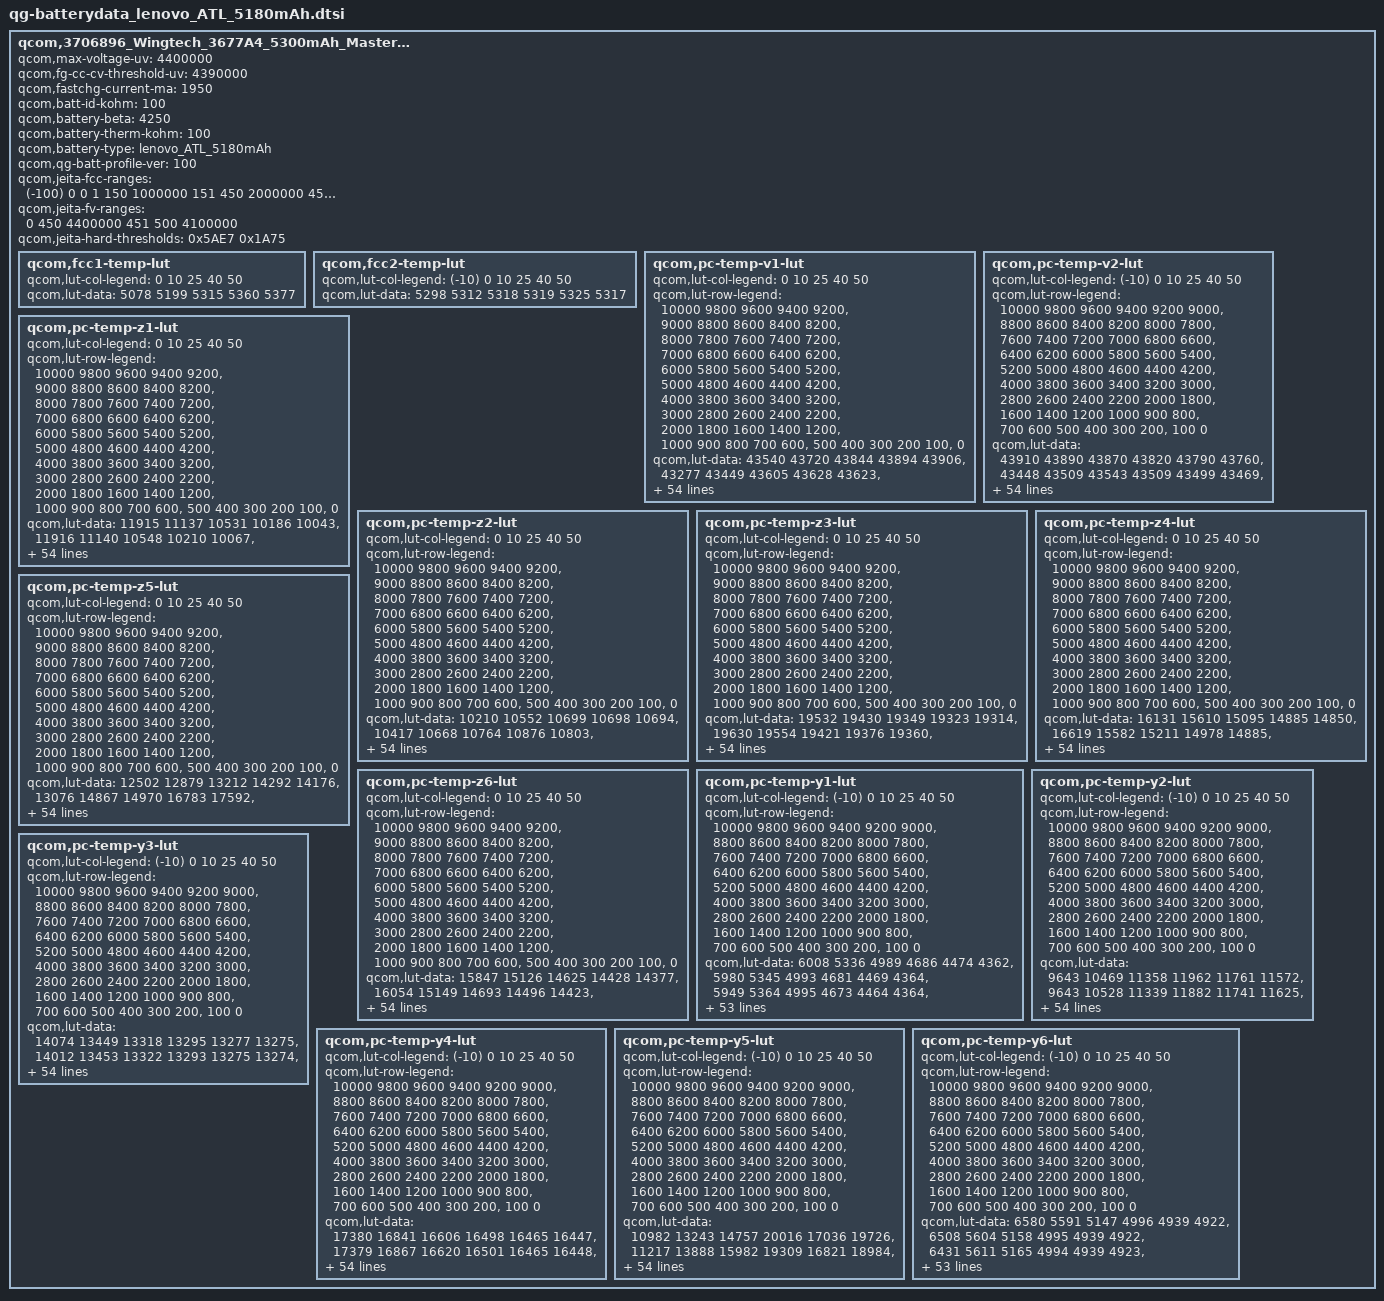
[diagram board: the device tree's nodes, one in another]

qcom,3706896_Wingtech_3677A4_5300mAh_Master_Oct16th2018 {
    /* 3706896_Wingtech_3677A4_5300mAh_Master_Oct16th2018 */
    qcom,max-voltage-uv = <4400000>;
    qcom,fg-cc-cv-threshold-uv = <4390000>;
    qcom,fastchg-current-ma = <1950>;
    qcom,batt-id-kohm = <100>;
    qcom,battery-beta = <4250>;
    qcom,battery-therm-kohm = <100>;
    qcom,battery-type = "lenovo_ATL_5180mAh";
    qcom,qg-batt-profile-ver = <100>;
    qcom,jeita-fcc-ranges = <(-100) 0 0
                       1 150 1000000
                       151 450 2000000
			451 500 1200000
			501 510 0>;
    qcom,jeita-fv-ranges = <0 450 4400000
                       451 500 4100000>;
    qcom,jeita-hard-thresholds = <0x5AE7 0x1A75>;

	qcom,fcc1-temp-lut {
		qcom,lut-col-legend = <0 10 25 40 50>;
		qcom,lut-data = <5078 5199 5315 5360 5377>;
	};

	qcom,fcc2-temp-lut {
		qcom,lut-col-legend = <(-10) 0 10 25 40 50>;
		qcom,lut-data = <5298 5312 5318 5319 5325 5317>;
	};

	qcom,pc-temp-v1-lut {
		qcom,lut-col-legend = <0 10 25 40 50>;
		qcom,lut-row-legend = <10000 9800 9600 9400 9200>,
			<9000 8800 8600 8400 8200>,
			<8000 7800 7600 7400 7200>,
			<7000 6800 6600 6400 6200>,
			<6000 5800 5600 5400 5200>,
			<5000 4800 4600 4400 4200>,
			<4000 3800 3600 3400 3200>,
			<3000 2800 2600 2400 2200>,
			<2000 1800 1600 1400 1200>,
			<1000 900 800 700 600>,
			<500 400 300 200 100>,
			<0>;
		qcom,lut-data = <43540 43720 43844 43894 43906>,
			<43277 43449 43605 43628 43623>,
			<43017 43194 43347 43384 43378>,
			<42765 42955 43098 43148 43144>,
			<42523 42722 42858 42912 42911>,
			<42288 42486 42621 42679 42679>,
			<42061 42253 42386 42446 42448>,
			<41839 42024 42152 42209 42215>,
			<41625 41800 41922 41977 41985>,
			<41420 41582 41693 41747 41756>,
			<41223 41370 41468 41521 41529>,
			<41025 41163 41251 41301 41308>,
			<40821 40960 41039 41085 41091>,
			<40617 40759 40834 40876 40881>,
			<40410 40561 40631 40671 40678>,
			<40197 40364 40437 40474 40481>,
			<40008 40167 40256 40287 40292>,
			<39859 39991 40083 40108 40109>,
			<39731 39846 39919 39937 39935>,
			<39604 39711 39769 39785 39779>,
			<39475 39567 39610 39627 39622>,
			<39350 39419 39415 39410 39418>,
			<39228 39256 39201 39133 39153>,
			<39109 39042 39000 38923 38940>,
			<38995 38819 38792 38794 38808>,
			<38886 38669 38634 38688 38700>,
			<38782 38560 38555 38588 38593>,
			<38681 38479 38498 38497 38491>,
			<38581 38420 38440 38410 38397>,
			<38493 38375 38380 38327 38309>,
			<38424 38335 38323 38251 38229>,
			<38364 38301 38266 38183 38157>,
			<38318 38267 38211 38125 38093>,
			<38285 38233 38161 38070 38034>,
			<38256 38198 38117 38024 37981>,
			<38223 38164 38074 37978 37929>,
			<38190 38132 38036 37929 37870>,
			<38149 38095 37997 37876 37808>,
			<38093 38035 37937 37809 37735>,
			<38021 37947 37842 37722 37647>,
			<37928 37845 37732 37621 37547>,
			<37799 37725 37621 37512 37436>,
			<37657 37588 37493 37387 37309>,
			<37500 37424 37333 37229 37153>,
			<37357 37274 37184 37086 37015>,
			<37246 37166 37079 36987 36922>,
			<37210 37135 37053 36958 36897>,
			<37176 37107 37029 36941 36878>,
			<37141 37079 37011 36920 36855>,
			<37083 37029 36956 36860 36787>,
			<36871 36798 36704 36593 36501>,
			<36427 36354 36271 36155 36058>,
			<35853 35778 35697 35580 35483>,
			<35078 34992 34915 34795 34697>,
			<33847 33760 33698 33574 33477>,
			<30000 30000 30000 30000 30000>;
	};

	qcom,pc-temp-v2-lut {
		qcom,lut-col-legend = <(-10) 0 10 25 40 50>;
		qcom,lut-row-legend = <10000 9800 9600 9400 9200 9000>,
			<8800 8600 8400 8200 8000 7800>,
			<7600 7400 7200 7000 6800 6600>,
			<6400 6200 6000 5800 5600 5400>,
			<5200 5000 4800 4600 4400 4200>,
			<4000 3800 3600 3400 3200 3000>,
			<2800 2600 2400 2200 2000 1800>,
			<1600 1400 1200 1000 900 800>,
			<700 600 500 400 300 200>,
			<100 0>;
		qcom,lut-data = <43910 43890 43870 43820 43790 43760>,
			<43448 43509 43543 43509 43499 43469>,
			<43038 43165 43240 43220 43226 43196>,
			<42692 42865 42967 42957 42971 42941>,
			<42394 42603 42722 42718 42735 42706>,
			<42127 42352 42483 42485 42504 42474>,
			<41881 42101 42239 42252 42271 42241>,
			<41655 41856 41999 42020 42039 42009>,
			<41444 41605 41767 41792 41810 41781>,
			<41247 41344 41540 41566 41583 41555>,
			<41053 41125 41320 41344 41361 41333>,
			<40872 40977 41106 41129 41147 41117>,
			<40682 40843 40897 40917 40938 40905>,
			<40413 40637 40691 40711 40730 40699>,
			<40010 40328 40487 40509 40521 40498>,
			<39659 40041 40288 40314 40322 40304>,
			<39441 39823 40100 40128 40136 40117>,
			<39262 39624 39913 39948 39959 39938>,
			<39078 39419 39707 39778 39790 39770>,
			<38893 39209 39482 39621 39632 39616>,
			<38725 39014 39265 39442 39455 39443>,
			<38576 38837 39062 39198 39218 39211>,
			<38446 38675 38874 38943 38974 38969>,
			<38346 38521 38716 38764 38796 38790>,
			<38267 38374 38578 38625 38653 38647>,
			<38200 38256 38456 38504 38530 38523>,
			<38141 38168 38345 38395 38422 38413>,
			<38087 38095 38244 38297 38325 38315>,
			<38034 38036 38150 38208 38234 38224>,
			<37984 37989 38060 38127 38149 38141>,
			<37933 37944 37984 38052 38073 38066>,
			<37882 37900 37918 37982 38004 37998>,
			<37829 37856 37862 37915 37940 37933>,
			<37772 37812 37813 37850 37877 37867>,
			<37713 37767 37773 37787 37816 37803>,
			<37651 37719 37731 37723 37745 37724>,
			<37588 37664 37688 37659 37649 37612>,
			<37522 37603 37643 37594 37547 37490>,
			<37448 37537 37586 37525 37461 37397>,
			<37367 37464 37518 37452 37385 37318>,
			<37286 37380 37438 37371 37303 37236>,
			<37213 37275 37339 37276 37211 37145>,
			<37140 37161 37222 37165 37107 37040>,
			<37067 37038 37076 37026 36980 36906>,
			<36980 36927 36927 36897 36846 36792>,
			<36882 36834 36839 36842 36802 36748>,
			<36834 36791 36810 36821 36788 36734>,
			<36767 36752 36783 36801 36765 36714>,
			<36673 36705 36737 36758 36731 36682>,
			<36532 36616 36643 36639 36638 36569>,
			<36268 36418 36395 36316 36346 36243>,
			<35838 36016 35906 35809 35856 35749>,
			<35227 35415 35269 35161 35218 35106>,
			<34329 34569 34387 34249 34325 34206>,
			<32902 33250 33031 32950 33060 32870>,
			<28842 29168 28189 28383 28551 28651>;
	};

	qcom,pc-temp-z1-lut {
		qcom,lut-col-legend = <0 10 25 40 50>;
		qcom,lut-row-legend = <10000 9800 9600 9400 9200>,
			<9000 8800 8600 8400 8200>,
			<8000 7800 7600 7400 7200>,
			<7000 6800 6600 6400 6200>,
			<6000 5800 5600 5400 5200>,
			<5000 4800 4600 4400 4200>,
			<4000 3800 3600 3400 3200>,
			<3000 2800 2600 2400 2200>,
			<2000 1800 1600 1400 1200>,
			<1000 900 800 700 600>,
			<500 400 300 200 100>,
			<0>;
		qcom,lut-data = <11915 11137 10531 10186 10043>,
			<11916 11140 10548 10210 10067>,
			<11941 11144 10577 10212 10069>,
			<11959 11151 10584 10212 10071>,
			<11956 11155 10569 10210 10069>,
			<11951 11154 10554 10203 10063>,
			<11950 11151 10549 10199 10060>,
			<11959 11145 10547 10196 10058>,
			<11965 11122 10544 10194 10057>,
			<11946 11100 10540 10193 10058>,
			<11898 11102 10537 10193 10059>,
			<11876 11112 10538 10192 10059>,
			<11888 11117 10539 10191 10057>,
			<11906 11114 10539 10189 10056>,
			<11903 11108 10536 10188 10057>,
			<11872 11105 10534 10188 10057>,
			<11844 11096 10534 10188 10057>,
			<11834 11088 10535 10188 10058>,
			<11827 11085 10536 10189 10059>,
			<11827 11084 10541 10191 10059>,
			<11855 11087 10546 10193 10060>,
			<11889 11100 10549 10194 10061>,
			<11906 11109 10552 10195 10061>,
			<11919 11117 10554 10195 10063>,
			<11927 11129 10556 10195 10065>,
			<11923 11131 10557 10195 10068>,
			<11913 11132 10563 10197 10070>,
			<11910 11134 10572 10203 10072>,
			<11900 11137 10576 10209 10073>,
			<11892 11140 10579 10213 10076>,
			<11889 11141 10582 10217 10079>,
			<11885 11135 10584 10220 10082>,
			<11883 11132 10585 10223 10085>,
			<11887 11139 10588 10226 10089>,
			<11893 11152 10594 10230 10092>,
			<11897 11158 10598 10234 10095>,
			<11903 11158 10601 10236 10096>,
			<11909 11158 10604 10238 10097>,
			<11921 11163 10608 10240 10098>,
			<11935 11175 10615 10244 10101>,
			<11938 11183 10621 10249 10104>,
			<11928 11187 10625 10255 10108>,
			<11924 11190 10630 10259 10112>,
			<11915 11192 10644 10259 10113>,
			<11891 11210 10653 10263 10114>,
			<11903 11213 10652 10267 10116>,
			<11895 11227 10662 10265 10117>,
			<11917 11200 10652 10274 10115>,
			<11922 11183 10661 10271 10118>,
			<11876 11201 10673 10273 10121>,
			<11929 11222 10675 10280 10126>,
			<11919 11232 10691 10286 10134>,
			<11948 11263 10698 10296 10140>,
			<11935 11290 10713 10310 10149>,
			<11935 11290 10713 10310 10149>,
			<11935 11290 10713 10310 10149>;
	};

	qcom,pc-temp-z2-lut {
		qcom,lut-col-legend = <0 10 25 40 50>;
		qcom,lut-row-legend = <10000 9800 9600 9400 9200>,
			<9000 8800 8600 8400 8200>,
			<8000 7800 7600 7400 7200>,
			<7000 6800 6600 6400 6200>,
			<6000 5800 5600 5400 5200>,
			<5000 4800 4600 4400 4200>,
			<4000 3800 3600 3400 3200>,
			<3000 2800 2600 2400 2200>,
			<2000 1800 1600 1400 1200>,
			<1000 900 800 700 600>,
			<500 400 300 200 100>,
			<0>;
		qcom,lut-data = <10210 10552 10699 10698 10694>,
			<10417 10668 10764 10876 10803>,
			<10531 10689 10834 10928 10878>,
			<10586 10649 10850 10964 10944>,
			<10593 10604 10783 10946 10945>,
			<10588 10577 10720 10916 10935>,
			<10581 10554 10709 10906 10923>,
			<10557 10548 10703 10905 10901>,
			<10533 10556 10703 10904 10886>,
			<10526 10564 10716 10914 10889>,
			<10518 10553 10733 10929 10898>,
			<10510 10524 10751 10931 10896>,
			<10499 10512 10776 10929 10855>,
			<10485 10527 10794 10926 10810>,
			<10479 10550 10808 10914 10777>,
			<10479 10566 10820 10899 10747>,
			<10478 10579 10833 10897 10738>,
			<10473 10595 10847 10896 10743>,
			<10469 10633 10862 10896 10751>,
			<10462 10676 10877 10894 10776>,
			<10435 10694 10895 10894 10812>,
			<10402 10708 10930 10931 10843>,
			<10381 10713 10972 11030 10921>,
			<10361 10711 10971 11071 10961>,
			<10352 10707 10885 10971 10954>,
			<10352 10701 10818 10860 10955>,
			<10354 10691 10830 10896 10986>,
			<10360 10685 10861 11034 11031>,
			<10379 10697 10897 11106 11048>,
			<10400 10722 10958 11088 10974>,
			<10412 10739 10995 11052 10883>,
			<10422 10750 10975 11016 10848>,
			<10432 10759 10939 10960 10791>,
			<10444 10765 10931 10939 10759>,
			<10457 10771 10937 10948 10778>,
			<10478 10777 10943 10967 10816>,
			<10508 10788 10952 11032 10884>,
			<10538 10802 10970 11151 11000>,
			<10566 10817 10995 11201 11040>,
			<10592 10834 11041 11216 11032>,
			<10610 10844 11079 11224 11026>,
			<10624 10847 11100 11202 11060>,
			<10649 10851 11111 11170 11111>,
			<10720 10870 11104 11172 11094>,
			<10669 11019 11138 11144 11054>,
			<12303 11162 11183 11211 10966>,
			<10108 11306 11156 11124 11025>,
			<10207 11453 11218 11123 11000>,
			<11393 11585 11265 11113 11064>,
			<15119 11853 11316 11355 11358>,
			<11221 11622 11345 11440 10947>,
			<12389 11349 11468 11283 10727>,
			<9775 11455 11379 11148 10720>,
			<9739 11104 11312 10982 10717>,
			<9739 11104 11312 10982 10717>,
			<9739 11104 11312 10982 10717>;
	};

	qcom,pc-temp-z3-lut {
		qcom,lut-col-legend = <0 10 25 40 50>;
		qcom,lut-row-legend = <10000 9800 9600 9400 9200>,
			<9000 8800 8600 8400 8200>,
			<8000 7800 7600 7400 7200>,
			<7000 6800 6600 6400 6200>,
			<6000 5800 5600 5400 5200>,
			<5000 4800 4600 4400 4200>,
			<4000 3800 3600 3400 3200>,
			<3000 2800 2600 2400 2200>,
			<2000 1800 1600 1400 1200>,
			<1000 900 800 700 600>,
			<500 400 300 200 100>,
			<0>;
		qcom,lut-data = <19532 19430 19349 19323 19314>,
			<19630 19554 19421 19376 19360>,
			<19673 19603 19472 19405 19385>,
			<19690 19621 19493 19417 19397>,
			<19672 19629 19503 19416 19396>,
			<19638 19630 19508 19413 19391>,
			<19628 19630 19501 19410 19386>,
			<19631 19626 19483 19406 19382>,
			<19637 19612 19472 19401 19377>,
			<19642 19595 19466 19395 19373>,
			<19648 19588 19460 19387 19369>,
			<19652 19583 19452 19380 19365>,
			<19652 19576 19443 19373 19359>,
			<19651 19562 19437 19367 19353>,
			<19651 19546 19433 19362 19345>,
			<19655 19535 19429 19359 19338>,
			<19657 19525 19420 19355 19335>,
			<19654 19518 19407 19351 19333>,
			<19651 19508 19403 19347 19332>,
			<19651 19500 19404 19345 19329>,
			<19659 19500 19404 19344 19327>,
			<19671 19506 19414 19347 19328>,
			<19682 19515 19431 19359 19334>,
			<19693 19528 19434 19364 19337>,
			<19701 19542 19429 19352 19327>,
			<19706 19544 19423 19338 19314>,
			<19709 19541 19415 19339 19318>,
			<19712 19538 19408 19346 19340>,
			<19717 19535 19407 19354 19354>,
			<19719 19532 19411 19369 19360>,
			<19717 19527 19417 19383 19364>,
			<19708 19521 19424 19382 19362>,
			<19698 19515 19433 19378 19355>,
			<19683 19514 19434 19373 19349>,
			<19665 19513 19429 19365 19341>,
			<19649 19512 19424 19358 19335>,
			<19631 19507 19417 19355 19333>,
			<19619 19501 19410 19351 19332>,
			<19609 19496 19406 19349 19330>,
			<19600 19492 19404 19347 19328>,
			<19595 19488 19403 19345 19326>,
			<19591 19482 19400 19343 19327>,
			<19582 19476 19396 19340 19329>,
			<19554 19467 19391 19339 19331>,
			<19385 19433 19381 19333 19328>,
			<19313 19418 19373 19331 19321>,
			<19265 19381 19361 19329 19311>,
			<19263 19367 19361 19319 19307>,
			<19262 19352 19326 19315 19307>,
			<19257 19328 19331 19305 19298>,
			<19260 19321 19324 19310 19312>,
			<19261 19309 19314 19312 19327>,
			<19269 19315 19315 19318 19322>,
			<19269 19313 19316 19312 19317>,
			<19269 19313 19316 19312 19317>,
			<19269 19313 19316 19312 19317>;
	};

	qcom,pc-temp-z4-lut {
		qcom,lut-col-legend = <0 10 25 40 50>;
		qcom,lut-row-legend = <10000 9800 9600 9400 9200>,
			<9000 8800 8600 8400 8200>,
			<8000 7800 7600 7400 7200>,
			<7000 6800 6600 6400 6200>,
			<6000 5800 5600 5400 5200>,
			<5000 4800 4600 4400 4200>,
			<4000 3800 3600 3400 3200>,
			<3000 2800 2600 2400 2200>,
			<2000 1800 1600 1400 1200>,
			<1000 900 800 700 600>,
			<500 400 300 200 100>,
			<0>;
		qcom,lut-data = <16131 15610 15095 14885 14850>,
			<16619 15582 15211 14978 14885>,
			<16468 15515 15130 14925 14851>,
			<16282 15346 15051 14864 14806>,
			<16097 15176 14971 14821 14778>,
			<15897 15082 14902 14783 14755>,
			<15733 15010 14857 14765 14743>,
			<15597 14949 14823 14756 14738>,
			<15482 14889 14800 14748 14733>,
			<15390 14844 14784 14742 14726>,
			<15312 14821 14772 14735 14719>,
			<15245 14805 14762 14729 14713>,
			<15185 14794 14754 14722 14707>,
			<15133 14784 14745 14715 14703>,
			<15093 14777 14734 14707 14698>,
			<15061 14774 14726 14699 14693>,
			<15033 14771 14722 14692 14686>,
			<15004 14769 14718 14685 14678>,
			<14976 14758 14712 14678 14671>,
			<14948 14743 14701 14671 14664>,
			<14919 14735 14693 14666 14658>,
			<14891 14728 14706 14688 14675>,
			<14866 14726 14738 14770 14755>,
			<14842 14765 14776 14816 14804>,
			<14825 14829 14841 14826 14810>,
			<14814 14850 14884 14831 14813>,
			<14806 14857 14875 14824 14803>,
			<14805 14860 14854 14798 14764>,
			<14805 14850 14832 14772 14732>,
			<14805 14826 14806 14740 14710>,
			<14805 14805 14781 14713 14693>,
			<14804 14787 14758 14699 14684>,
			<14803 14771 14736 14690 14677>,
			<14801 14756 14726 14686 14674>,
			<14797 14742 14720 14684 14674>,
			<14793 14731 14716 14682 14673>,
			<14789 14721 14713 14684 14675>,
			<14785 14715 14711 14688 14682>,
			<14777 14716 14712 14694 14688>,
			<14767 14720 14724 14705 14697>,
			<14762 14721 14733 14712 14703>,
			<14757 14718 14724 14707 14698>,
			<14756 14715 14713 14701 14690>,
			<14761 14715 14712 14703 14692>,
			<14858 14709 14700 14701 14689>,
			<14914 14697 14684 14681 14678>,
			<14963 14729 14682 14673 14676>,
			<14956 14734 14667 14664 14662>,
			<14948 14743 14692 14649 14641>,
			<14941 14765 14683 14659 14648>,
			<14939 14785 14716 14684 14668>,
			<14962 14811 14735 14687 14657>,
			<14975 14809 14737 14682 14663>,
			<14991 14823 14741 14692 14671>,
			<14991 14823 14741 14692 14671>,
			<14991 14823 14741 14692 14671>;
	};

	qcom,pc-temp-z5-lut {
		qcom,lut-col-legend = <0 10 25 40 50>;
		qcom,lut-row-legend = <10000 9800 9600 9400 9200>,
			<9000 8800 8600 8400 8200>,
			<8000 7800 7600 7400 7200>,
			<7000 6800 6600 6400 6200>,
			<6000 5800 5600 5400 5200>,
			<5000 4800 4600 4400 4200>,
			<4000 3800 3600 3400 3200>,
			<3000 2800 2600 2400 2200>,
			<2000 1800 1600 1400 1200>,
			<1000 900 800 700 600>,
			<500 400 300 200 100>,
			<0>;
		qcom,lut-data = <12502 12879 13212 14292 14176>,
			<13076 14867 14970 16783 17592>,
			<13586 15964 16588 18374 19860>,
			<14043 16534 17774 19493 21322>,
			<14420 16999 18646 20407 22266>,
			<14766 17538 19334 21157 22947>,
			<15121 18136 19886 21507 23119>,
			<15499 18830 20364 21818 22888>,
			<15850 19786 20859 21978 22630>,
			<16171 20752 21420 21881 22736>,
			<16484 21584 21853 21695 23055>,
			<16610 22410 22007 21537 23085>,
			<16604 22732 22033 21277 22717>,
			<16587 22657 22195 21053 22255>,
			<16601 22538 23153 21320 21670>,
			<16765 22403 23898 21800 21053>,
			<16883 22013 23417 21933 21103>,
			<16827 21825 22449 22252 22184>,
			<16753 22211 22345 22738 23483>,
			<16813 23050 23995 23626 24650>,
			<17395 24542 26907 25106 25915>,
			<18352 28156 35785 28849 27536>,
			<19603 33004 48841 36683 30011>,
			<21496 42023 51222 39811 31099>,
			<23575 51859 44192 31197 25148>,
			<25710 53066 36306 21063 17481>,
			<28119 48006 30814 19118 16887>,
			<31183 42706 26196 18600 18293>,
			<35632 39727 24728 19037 19705>,
			<38579 37327 24489 22018 22122>,
			<38679 35437 24803 25889 24880>,
			<38153 33672 27671 28869 26599>,
			<37183 32680 32808 31647 28120>,
			<34040 33549 36216 33144 29103>,
			<30213 35666 39206 33720 29793>,
			<27782 36581 40773 33891 30182>,
			<25821 36579 39975 33813 30088>,
			<24597 36469 38177 33409 29662>,
			<24333 36409 36568 32340 28797>,
			<24627 36183 35005 29166 25537>,
			<25142 35701 33490 26056 22822>,
			<26268 33617 31872 24590 22847>,
			<26364 31330 30208 23549 23133>,
			<23311 29087 27902 22782 22810>,
			<15819 25402 27524 21457 22066>,
			<13158 24612 27555 22105 20734>,
			<11839 18006 23314 22281 18596>,
			<11789 16222 24118 20274 18791>,
			<11781 15261 16558 21020 22201>,
			<11770 14069 17506 18331 18698>,
			<11854 13804 15903 16087 17134>,
			<11797 13143 14380 15574 19308>,
			<11730 13119 14122 15763 17486>,
			<11593 12787 13856 14695 15864>,
			<11593 12787 13856 14695 15864>,
			<11593 12787 13856 14695 15864>;
	};

	qcom,pc-temp-z6-lut {
		qcom,lut-col-legend = <0 10 25 40 50>;
		qcom,lut-row-legend = <10000 9800 9600 9400 9200>,
			<9000 8800 8600 8400 8200>,
			<8000 7800 7600 7400 7200>,
			<7000 6800 6600 6400 6200>,
			<6000 5800 5600 5400 5200>,
			<5000 4800 4600 4400 4200>,
			<4000 3800 3600 3400 3200>,
			<3000 2800 2600 2400 2200>,
			<2000 1800 1600 1400 1200>,
			<1000 900 800 700 600>,
			<500 400 300 200 100>,
			<0>;
		qcom,lut-data = <15847 15126 14625 14428 14377>,
			<16054 15149 14693 14496 14423>,
			<15972 15141 14686 14486 14419>,
			<15868 15061 14674 14471 14411>,
			<15749 14970 14642 14454 14401>,
			<15614 14922 14605 14433 14387>,
			<15515 14884 14578 14422 14378>,
			<15443 14845 14554 14415 14373>,
			<15385 14800 14537 14409 14368>,
			<15338 14765 14526 14402 14363>,
			<15300 14752 14517 14396 14357>,
			<15264 14745 14508 14389 14352>,
			<15225 14736 14499 14382 14346>,
			<15192 14721 14492 14375 14340>,
			<15171 14706 14485 14369 14334>,
			<15157 14699 14479 14363 14328>,
			<15144 14695 14471 14357 14323>,
			<15129 14689 14463 14352 14319>,
			<15112 14677 14458 14347 14314>,
			<15105 14665 14455 14343 14310>,
			<15102 14664 14454 14341 14307>,
			<15101 14668 14464 14353 14315>,
			<15098 14674 14488 14396 14353>,
			<15095 14700 14508 14416 14374>,
			<15094 14736 14533 14413 14373>,
			<15096 14747 14547 14410 14369>,
			<15100 14750 14542 14407 14366>,
			<15101 14751 14530 14402 14361>,
			<15101 14747 14521 14397 14357>,
			<15101 14738 14514 14392 14352>,
			<15100 14728 14508 14387 14348>,
			<15098 14714 14503 14381 14342>,
			<15095 14704 14499 14376 14336>,
			<15087 14701 14495 14371 14331>,
			<15078 14699 14491 14366 14326>,
			<15072 14697 14488 14363 14323>,
			<15065 14691 14483 14362 14323>,
			<15060 14687 14479 14362 14325>,
			<15056 14687 14479 14363 14326>,
			<15052 14688 14486 14367 14329>,
			<15051 14689 14491 14370 14331>,
			<15051 14691 14487 14368 14330>,
			<15050 14692 14483 14364 14328>,
			<15044 14691 14482 14365 14330>,
			<15004 14682 14476 14361 14328>,
			<14991 14667 14466 14352 14320>,
			<14988 14666 14460 14348 14314>,
			<14985 14660 14454 14340 14305>,
			<14982 14657 14449 14331 14296>,
			<14985 14658 14450 14331 14295>,
			<14992 14675 14464 14345 14313>,
			<15011 14689 14470 14350 14318>,
			<15037 14696 14476 14353 14320>,
			<15060 14717 14485 14358 14323>,
			<15060 14717 14485 14358 14323>,
			<15060 14717 14485 14358 14323>;
	};

	qcom,pc-temp-y1-lut {
		qcom,lut-col-legend = <(-10) 0 10 25 40 50>;
		qcom,lut-row-legend = <10000 9800 9600 9400 9200 9000>,
			<8800 8600 8400 8200 8000 7800>,
			<7600 7400 7200 7000 6800 6600>,
			<6400 6200 6000 5800 5600 5400>,
			<5200 5000 4800 4600 4400 4200>,
			<4000 3800 3600 3400 3200 3000>,
			<2800 2600 2400 2200 2000 1800>,
			<1600 1400 1200 1000 900 800>,
			<700 600 500 400 300 200>,
			<100 0>;
		qcom,lut-data = <6008 5336 4989 4686 4474 4362>,
			<5980 5345 4993 4681 4469 4364>,
			<5949 5364 4995 4673 4464 4364>,
			<5920 5385 4996 4664 4459 4364>,
			<5898 5402 4996 4657 4455 4364>,
			<5890 5410 4994 4653 4451 4363>,
			<5896 5409 4991 4652 4448 4360>,
			<5904 5408 4986 4651 4446 4357>,
			<5905 5408 4983 4651 4444 4355>,
			<5898 5411 4979 4651 4442 4354>,
			<5892 5410 4977 4651 4440 4353>,
			<5888 5396 4980 4647 4437 4353>,
			<5884 5379 4984 4639 4434 4352>,
			<5891 5379 4985 4635 4434 4352>,
			<5917 5391 4983 4632 4436 4352>,
			<5934 5399 4984 4631 4437 4352>,
			<5921 5392 4990 4634 4435 4352>,
			<5902 5383 4997 4638 4434 4353>,
			<5901 5384 4997 4640 4433 4353>,
			<5915 5397 4987 4641 4434 4353>,
			<5924 5407 4981 4642 4435 4353>,
			<5920 5408 4976 4644 4434 4353>,
			<5913 5406 4971 4646 4434 4354>,
			<5914 5404 4971 4646 4434 4353>,
			<5922 5400 4975 4646 4435 4351>,
			<5929 5399 4978 4647 4435 4349>,
			<5925 5405 4982 4651 4438 4352>,
			<5913 5413 4985 4655 4440 4357>,
			<5896 5410 4984 4658 4441 4358>,
			<5866 5391 4980 4661 4441 4360>,
			<5848 5379 4978 4664 4442 4361>,
			<5859 5384 4983 4668 4445 4363>,
			<5874 5393 4990 4672 4449 4366>,
			<5877 5398 4993 4675 4452 4368>,
			<5875 5400 4995 4677 4455 4370>,
			<5874 5400 4996 4680 4458 4371>,
			<5866 5388 4993 4685 4460 4373>,
			<5856 5371 4992 4689 4462 4374>,
			<5853 5368 5001 4689 4465 4375>,
			<5853 5371 5023 4686 4468 4375>,
			<5857 5375 5032 4685 4469 4376>,
			<5900 5382 5015 4698 4470 4383>,
			<5940 5388 5004 4707 4472 4388>,
			<5917 5381 5014 4703 4480 4383>,
			<5899 5372 5012 4706 4478 4386>,
			<5845 5403 5036 4721 4485 4386>,
			<5861 5375 5011 4726 4488 4389>,
			<5924 5380 5017 4722 4483 4391>,
			<5907 5371 5006 4727 4483 4389>,
			<5880 5371 5019 4729 4486 4389>,
			<5942 5370 5022 4734 4488 4391>,
			<5894 5387 5034 4749 4495 4395>,
			<5966 5378 5047 4770 4501 4400>,
			<6035 5417 5075 4787 4509 4405>,
			<6035 5417 5075 4787 4509 4405>,
			<6035 5417 5075 4787 4509 4405>;
	};

	qcom,pc-temp-y2-lut {
		qcom,lut-col-legend = <(-10) 0 10 25 40 50>;
		qcom,lut-row-legend = <10000 9800 9600 9400 9200 9000>,
			<8800 8600 8400 8200 8000 7800>,
			<7600 7400 7200 7000 6800 6600>,
			<6400 6200 6000 5800 5600 5400>,
			<5200 5000 4800 4600 4400 4200>,
			<4000 3800 3600 3400 3200 3000>,
			<2800 2600 2400 2200 2000 1800>,
			<1600 1400 1200 1000 900 800>,
			<700 600 500 400 300 200>,
			<100 0>;
		qcom,lut-data = <9643 10469 11358 11962 11761 11572>,
			<9643 10528 11339 11882 11741 11625>,
			<9643 10596 11317 11780 11706 11636>,
			<9729 10663 11291 11673 11663 11615>,
			<9843 10717 11266 11583 11622 11571>,
			<9944 10744 11241 11529 11590 11512>,
			<10041 10750 11214 11501 11524 11404>,
			<10123 10750 11187 11479 11444 11292>,
			<10159 10772 11165 11464 11432 11287>,
			<10179 10876 11143 11447 11459 11349>,
			<10196 10937 11133 11438 11477 11387>,
			<10375 10966 11141 11435 11491 11331>,
			<10639 11014 11159 11433 11509 11247>,
			<10585 11033 11193 11439 11518 11243>,
			<10033 11071 11266 11469 11547 11318>,
			<9675 11098 11326 11507 11558 11363>,
			<9675 11109 11356 11558 11541 11355>,
			<9676 11121 11378 11614 11525 11345>,
			<9676 11141 11390 11653 11567 11380>,
			<9675 11176 11396 11686 11746 11528>,
			<9674 11199 11407 11703 11840 11627>,
			<9673 11206 11439 11703 11775 11645>,
			<9672 11211 11482 11701 11684 11652>,
			<9671 11113 11508 11718 11662 11643>,
			<9670 10736 11538 11770 11672 11608>,
			<9668 10543 11560 11820 11693 11592>,
			<9667 10313 11581 11864 11757 11599>,
			<9666 9945 11607 11897 11822 11612>,
			<9665 9836 11639 11890 11824 11644>,
			<9664 9797 11682 11850 11805 11727>,
			<9663 9766 11701 11830 11790 11802>,
			<9662 9739 11696 11851 11775 11854>,
			<9661 9717 11686 11879 11769 11904>,
			<9660 9701 11671 11884 11810 11960>,
			<9659 9689 11636 11873 11901 12026>,
			<9658 9681 11590 11862 11938 12051>,
			<9658 9675 11521 11831 11877 11939>,
			<9658 9671 11441 11791 11810 11793>,
			<9658 9667 11378 11764 11823 11739>,
			<9658 9664 11318 11722 11876 11679>,
			<9657 9662 11245 11695 11895 11647>,
			<9657 9660 11141 11666 11828 11617>,
			<9657 9659 11034 11626 11780 11599>,
			<9657 9658 10936 11510 11884 11599>,
			<9657 9657 10467 11292 11769 11626>,
			<9657 9657 10249 11481 11679 11373>,
			<9656 9657 9830 11451 11792 11295>,
			<9656 9656 10263 11393 11508 11426>,
			<9656 9656 10229 11364 11453 11333>,
			<9656 9656 10200 11276 11633 11247>,
			<9656 9656 10119 11226 11584 11245>,
			<9656 9655 9848 11164 11597 11301>,
			<9655 9655 9723 11008 11305 11054>,
			<9652 9655 9686 10912 11037 10896>,
			<9652 9655 9686 10912 11037 10896>,
			<9652 9655 9686 10912 11037 10896>;
	};

	qcom,pc-temp-y3-lut {
		qcom,lut-col-legend = <(-10) 0 10 25 40 50>;
		qcom,lut-row-legend = <10000 9800 9600 9400 9200 9000>,
			<8800 8600 8400 8200 8000 7800>,
			<7600 7400 7200 7000 6800 6600>,
			<6400 6200 6000 5800 5600 5400>,
			<5200 5000 4800 4600 4400 4200>,
			<4000 3800 3600 3400 3200 3000>,
			<2800 2600 2400 2200 2000 1800>,
			<1600 1400 1200 1000 900 800>,
			<700 600 500 400 300 200>,
			<100 0>;
		qcom,lut-data = <14074 13449 13318 13295 13277 13275>,
			<14012 13453 13322 13293 13275 13274>,
			<13918 13457 13327 13292 13275 13273>,
			<13817 13459 13332 13292 13275 13272>,
			<13732 13460 13336 13292 13276 13272>,
			<13690 13461 13338 13292 13276 13272>,
			<13681 13460 13339 13293 13278 13273>,
			<13676 13458 13340 13294 13280 13273>,
			<13650 13456 13341 13295 13280 13274>,
			<13566 13452 13344 13295 13281 13274>,
			<13507 13446 13345 13295 13281 13274>,
			<13500 13430 13346 13297 13282 13276>,
			<13497 13409 13347 13301 13283 13279>,
			<13490 13405 13346 13302 13283 13279>,
			<13476 13406 13345 13302 13281 13278>,
			<13461 13407 13343 13301 13281 13278>,
			<13446 13400 13342 13301 13282 13278>,
			<13430 13389 13341 13302 13284 13278>,
			<13420 13381 13338 13302 13286 13279>,
			<13411 13373 13332 13303 13288 13283>,
			<13404 13367 13326 13304 13288 13285>,
			<13399 13362 13321 13300 13285 13281>,
			<13395 13357 13317 13294 13281 13276>,
			<13397 13345 13314 13290 13278 13273>,
			<13411 13320 13311 13288 13276 13272>,
			<13428 13305 13310 13286 13275 13271>,
			<13445 13290 13308 13285 13276 13271>,
			<13464 13271 13306 13284 13277 13271>,
			<13485 13268 13304 13284 13277 13271>,
			<13511 13273 13300 13287 13276 13272>,
			<13540 13279 13298 13288 13275 13272>,
			<13578 13288 13299 13288 13275 13272>,
			<13629 13300 13299 13288 13275 13273>,
			<13683 13316 13300 13288 13276 13273>,
			<13749 13339 13302 13288 13278 13274>,
			<13806 13364 13303 13287 13278 13274>,
			<13844 13391 13305 13287 13278 13273>,
			<13878 13422 13309 13286 13277 13271>,
			<13923 13463 13311 13285 13276 13271>,
			<13988 13516 13314 13283 13275 13272>,
			<14057 13575 13316 13282 13275 13273>,
			<14133 13640 13320 13285 13275 13274>,
			<14192 13708 13323 13287 13275 13274>,
			<14216 13775 13324 13287 13274 13271>,
			<14284 13842 13325 13287 13271 13271>,
			<14248 13843 13326 13288 13276 13272>,
			<14308 13894 13330 13289 13279 13275>,
			<14429 13967 13349 13295 13278 13278>,
			<14459 14024 13353 13302 13281 13283>,
			<14583 14068 13373 13306 13286 13281>,
			<14707 14138 13395 13305 13282 13277>,
			<14765 14215 13397 13306 13282 13277>,
			<15012 14330 13454 13317 13284 13280>,
			<15859 14512 13560 13333 13286 13283>,
			<15859 14512 13560 13333 13286 13283>,
			<15859 14512 13560 13333 13286 13283>;
	};

	qcom,pc-temp-y4-lut {
		qcom,lut-col-legend = <(-10) 0 10 25 40 50>;
		qcom,lut-row-legend = <10000 9800 9600 9400 9200 9000>,
			<8800 8600 8400 8200 8000 7800>,
			<7600 7400 7200 7000 6800 6600>,
			<6400 6200 6000 5800 5600 5400>,
			<5200 5000 4800 4600 4400 4200>,
			<4000 3800 3600 3400 3200 3000>,
			<2800 2600 2400 2200 2000 1800>,
			<1600 1400 1200 1000 900 800>,
			<700 600 500 400 300 200>,
			<100 0>;
		qcom,lut-data = <17380 16841 16606 16498 16465 16447>,
			<17379 16867 16620 16501 16465 16448>,
			<17392 16926 16636 16504 16465 16449>,
			<17410 16996 16652 16507 16465 16451>,
			<17421 17054 16664 16510 16465 16452>,
			<17416 17078 16670 16513 16465 16453>,
			<17393 17078 16670 16514 16465 16454>,
			<17373 17078 16668 16516 16466 16456>,
			<17397 17075 16670 16519 16467 16458>,
			<17543 17063 16675 16526 16471 16462>,
			<17638 17058 16682 16533 16476 16465>,
			<17605 17169 16691 16537 16485 16467>,
			<17528 17328 16704 16542 16496 16469>,
			<17422 17316 16727 16550 16502 16473>,
			<17235 17128 16767 16567 16506 16480>,
			<17097 16991 16792 16585 16512 16488>,
			<17052 16957 16799 16605 16520 16496>,
			<17020 16931 16803 16628 16532 16504>,
			<16977 16891 16792 16654 16552 16517>,
			<16922 16833 16733 16687 16589 16537>,
			<16877 16778 16672 16701 16606 16546>,
			<16846 16728 16621 16626 16559 16520>,
			<16823 16687 16577 16522 16494 16481>,
			<16814 16667 16557 16495 16473 16465>,
			<16810 16650 16544 16485 16463 16457>,
			<16807 16644 16537 16482 16459 16454>,
			<16805 16665 16535 16485 16460 16456>,
			<16803 16695 16534 16491 16463 16459>,
			<16803 16701 16532 16496 16468 16463>,
			<16806 16702 16530 16502 16477 16470>,
			<16809 16702 16528 16508 16487 16478>,
			<16814 16704 16524 16515 16499 16489>,
			<16820 16709 16520 16521 16509 16498>,
			<16826 16712 16521 16520 16514 16503>,
			<16831 16717 16527 16516 16517 16507>,
			<16834 16721 16535 16511 16517 16508>,
			<16834 16727 16544 16501 16494 16490>,
			<16833 16734 16556 16492 16468 16466>,
			<16835 16739 16568 16492 16465 16462>,
			<16838 16746 16580 16495 16465 16461>,
			<16843 16747 16590 16498 16465 16460>,
			<16850 16737 16598 16503 16468 16461>,
			<16862 16727 16600 16509 16470 16462>,
			<16887 16719 16598 16519 16471 16461>,
			<16920 16713 16603 16516 16461 16450>,
			<16884 16705 16606 16516 16464 16460>,
			<16896 16723 16644 16533 16471 16470>,
			<16923 16748 16648 16556 16491 16488>,
			<16947 16784 16706 16583 16516 16510>,
			<16952 16831 16747 16596 16516 16510>,
			<16940 16845 16749 16578 16485 16467>,
			<16926 16813 16746 16575 16472 16461>,
			<16944 16803 16778 16614 16482 16466>,
			<17275 16838 16830 16689 16509 16485>,
			<17275 16838 16830 16689 16509 16485>,
			<17275 16838 16830 16689 16509 16485>;
	};

	qcom,pc-temp-y5-lut {
		qcom,lut-col-legend = <(-10) 0 10 25 40 50>;
		qcom,lut-row-legend = <10000 9800 9600 9400 9200 9000>,
			<8800 8600 8400 8200 8000 7800>,
			<7600 7400 7200 7000 6800 6600>,
			<6400 6200 6000 5800 5600 5400>,
			<5200 5000 4800 4600 4400 4200>,
			<4000 3800 3600 3400 3200 3000>,
			<2800 2600 2400 2200 2000 1800>,
			<1600 1400 1200 1000 900 800>,
			<700 600 500 400 300 200>,
			<100 0>;
		qcom,lut-data = <10982 13243 14757 20016 17036 19726>,
			<11217 13888 15982 19309 16821 18984>,
			<11658 14594 16940 18460 16623 18171>,
			<12267 15276 17627 17612 16445 17385>,
			<13009 15847 18040 16909 16296 16727>,
			<13846 16222 18174 16496 16181 16300>,
			<15070 16458 17905 16337 16458 16089>,
			<16259 16614 17456 16227 16896 15931>,
			<16271 16489 17246 15963 16794 15668>,
			<14983 15794 17072 15332 16339 15257>,
			<14222 15350 16868 14981 15974 15049>,
			<16576 15764 16349 15228 15961 15558>,
			<20097 16485 15760 15585 16035 16295>,
			<19952 17179 15715 15522 15685 16282>,
			<15637 18844 15993 14964 14638 15599>,
			<12836 19840 16406 14600 14086 14960>,
			<12964 19747 17473 14626 14171 14529>,
			<13183 19592 18890 14792 14357 14221>,
			<13231 19583 19713 15509 14609 14323>,
			<13096 19784 20307 17835 15043 15077>,
			<12914 19973 20636 19639 15698 16033>,
			<12546 20227 20389 20498 17574 17475>,
			<12086 20508 19904 21043 19630 18820>,
			<11933 19899 19663 20786 19895 18791>,
			<11884 17350 19158 19413 19151 17893>,
			<11876 15732 18931 18282 18764 17186>,
			<11949 14079 18660 17577 19037 16749>,
			<12056 11958 18206 17074 19210 16409>,
			<12099 11587 17796 17318 18659 16388>,
			<12152 11693 16746 18584 17579 16500>,
			<12212 11796 16272 19626 17104 16649>,
			<12299 11907 16417 20181 17314 16826>,
			<12402 12075 16622 20583 17751 17082>,
			<12456 12319 16792 20818 18689 17679>,
			<12483 12687 17047 20981 20483 18894>,
			<12501 12948 17125 21011 21278 19455>,
			<12567 13066 17501 20532 21216 18843>,
			<12656 13152 18038 19798 21037 18076>,
			<12614 13240 18168 18902 20597 18127>,
			<12305 13364 18260 17179 19632 18672>,
			<12104 13407 18312 16417 18794 19049>,
			<12182 13251 18599 17124 18161 19052>,
			<12276 13027 18806 17541 17751 18752>,
			<12284 12807 17877 16658 17480 16423>,
			<12249 12795 15651 16323 16051 17496>,
			<12274 12669 14284 16406 16994 15723>,
			<12609 12543 13483 15590 17303 16381>,
			<12819 12777 15127 15927 15552 16648>,
			<12774 13166 14793 16375 15995 17664>,
			<13250 13136 15002 17038 17724 16580>,
			<13081 13239 15661 17433 17208 16074>,
			<12407 13048 13521 17635 18782 16992>,
			<12396 12677 13325 18208 18069 18762>,
			<11364 12388 13518 19481 17870 19696>,
			<11364 12388 13518 19481 17870 19696>,
			<11364 12388 13518 19481 17870 19696>;
	};

	qcom,pc-temp-y6-lut {
		qcom,lut-col-legend = <(-10) 0 10 25 40 50>;
		qcom,lut-row-legend = <10000 9800 9600 9400 9200 9000>,
			<8800 8600 8400 8200 8000 7800>,
			<7600 7400 7200 7000 6800 6600>,
			<6400 6200 6000 5800 5600 5400>,
			<5200 5000 4800 4600 4400 4200>,
			<4000 3800 3600 3400 3200 3000>,
			<2800 2600 2400 2200 2000 1800>,
			<1600 1400 1200 1000 900 800>,
			<700 600 500 400 300 200>,
			<100 0>;
		qcom,lut-data = <6580 5591 5147 4996 4939 4922>,
			<6508 5604 5158 4995 4939 4922>,
			<6431 5611 5165 4994 4939 4923>,
			<6357 5613 5170 4994 4939 4923>,
			<6295 5611 5172 4993 4939 4923>,
			<6253 5607 5173 4993 4939 4924>,
			<6231 5599 5170 4994 4940 4924>,
			<6215 5588 5166 4995 4941 4925>,
			<6190 5576 5164 4995 4942 4926>,
			<6152 5561 5164 4997 4943 4927>,
			<6125 5554 5165 4999 4944 4928>,
			<6116 5568 5166 5001 4948 4930>,
			<6108 5588 5167 5004 4952 4932>,
			<6084 5582 5171 5007 4953 4934>,
			<6010 5535 5180 5011 4954 4935>,
			<5940 5496 5185 5016 4955 4937>,
			<5896 5479 5186 5022 4958 4939>,
			<5862 5465 5185 5028 4962 4941>,
			<5846 5450 5178 5036 4969 4946>,
			<5838 5433 5157 5046 4981 4953>,
			<5832 5418 5135 5050 4987 4957>,
			<5829 5403 5118 5026 4971 4948>,
			<5831 5390 5103 4992 4948 4933>,
			<5839 5384 5095 4982 4940 4926>,
			<5856 5379 5090 4978 4936 4922>,
			<5875 5378 5088 4977 4934 4921>,
			<5892 5383 5088 4978 4935 4922>,
			<5911 5395 5089 4979 4936 4923>,
			<5929 5408 5089 4981 4938 4924>,
			<5952 5426 5090 4984 4940 4927>,
			<5976 5448 5090 4988 4943 4930>,
			<6013 5477 5093 4991 4946 4933>,
			<6065 5511 5096 4994 4950 4937>,
			<6113 5545 5100 4995 4952 4939>,
			<6168 5581 5106 4994 4955 4940>,
			<6212 5620 5114 4993 4955 4940>,
			<6239 5662 5125 4991 4948 4934>,
			<6263 5708 5138 4988 4940 4926>,
			<6295 5760 5153 4988 4939 4926>,
			<6346 5820 5172 4989 4939 4926>,
			<6403 5880 5192 4991 4939 4927>,
			<6469 5939 5216 4996 4940 4928>,
			<6520 5996 5241 5002 4941 4928>,
			<6536 6048 5268 5007 4941 4926>,
			<6595 6104 5285 5010 4937 4923>,
			<6566 6105 5296 5012 4942 4927>,
			<6609 6148 5314 5020 4946 4933>,
			<6713 6207 5349 5033 4951 4939>,
			<6736 6257 5391 5047 4961 4949>,
			<6835 6307 5443 5056 4964 4949>,
			<6935 6367 5478 5053 4953 4933>,
			<6973 6418 5508 5060 4950 4932>,
			<7180 6502 5598 5088 4956 4937>,
			<8016 6657 5733 5134 4967 4946>,
			<8016 6657 5733 5134 4967 4946>,
			<8016 6657 5733 5134 4967 4946>;
	};

};
